# GD32C211 register map
File version: 1.0
CPU: CM23 r0p0, little endian, MPU, FPU, 4 interrupt priority bits
Registers are 32-bit, read-write, reset 0x0 unless marked. A register's access mark holds for its fields unless they carry their own. Offsets are from the block's base; [hi:lo] are bit positions.

## WWDGT — Window watchdog timer
Base 0x40002C00
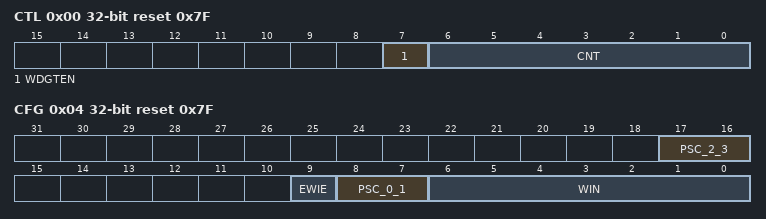
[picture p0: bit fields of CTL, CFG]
0x00 CTL reset 0x7F — Control register
  [7] WDGTEN — Activation bit
  [6:0] CNT — 7-bit counter
0x04 CFG reset 0x7F — Configuration register
  [17:16] PSC_2_3 — Prescaler
  [9] EWIE — Early wakeup interrupt
  [8:7] PSC_0_1 — Prescaler
  [6:0] WIN — 7-bit window value
0x08 STAT — Status register
  [0] EWIF — Early wakeup interrupt flag

## RTC — Real time clock
Base 0x40002800
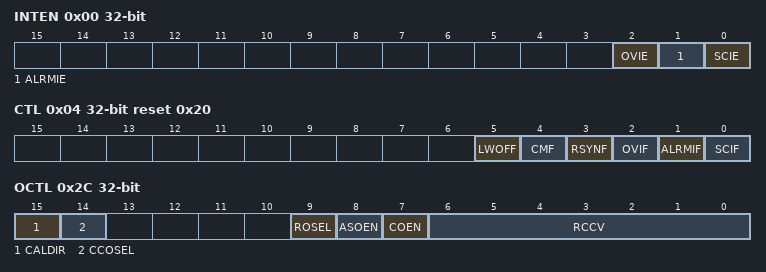
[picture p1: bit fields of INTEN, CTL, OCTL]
0x00 INTEN — RTC interrupt enable register
  [2] OVIE — Overflow interrupt enable
  [1] ALRMIE — Alarm interrupt enable
  [0] SCIE — Second interrupt enable
0x04 CTL access per field reset 0x20 — RTC control register
  [5] LWOFF ro — Last write operation finished flag
  [4] CMF rw — Configuration mode flag
  [3] RSYNF rw — Registers synchronized flag
  [2] OVIF rw — Overflow interrupt flag
  [1] ALRMIF rw — Alarm interrupt flag
  [0] SCIF rw — Second interrupt flag
0x08 PSCH wo — RTC prescaler high register
  [3:0] PSC — RTC prescaler value high
0x0C PSCL wo reset 0x8000 — RTC prescaler low register
  [15:0] PSC — RTC prescaler value low
0x10 DIVH ro — RTC divider high register
  [3:0] DIV — RTC divider value high
0x14 DIVL ro reset 0x8000 — RTC divider low register
  [15:0] DIV — RTC divider value low
0x18 CNTH — RTC counter high register
  [15:0] CNT — RTC counter value high
0x1C CNTL — RTC counter low register
  [15:0] CNT — RTC counter value low
0x20 ALRMH wo reset 0xFFFF — RTC alarm high register
  [15:0] ALRM — RTC alarm value high
0x24 ALRML wo — RTC alarm low register
  [15:0] ALRM — RTC alarm value low
0x2C OCTL — RTC signal output control register
  [15] CALDIR — RTC clock calibration direction
  [14] CCOSEL — RTC clock output selection
  [9] ROSEL — RTC output selection
  [8] ASOEN — RTC alarm or second signal output enable
  [7] COEN — RTC clock calibration output enable
  [6:0] RCCV — RTC clock calibration value

## SPI1 — Serial peripheral interface
Base 0x40003800
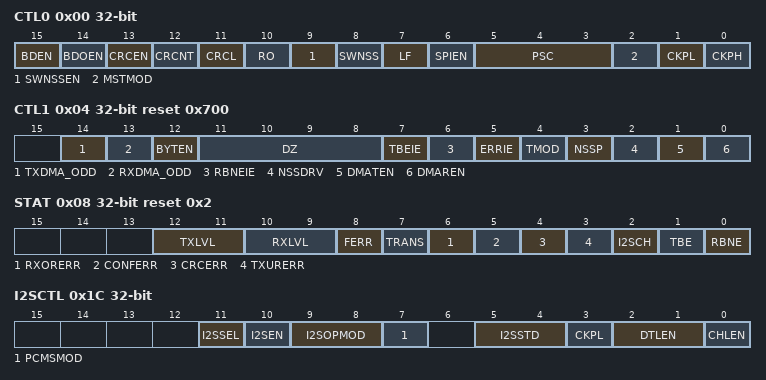
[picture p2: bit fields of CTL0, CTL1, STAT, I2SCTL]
0x00 CTL0 — control register 0
  [15] BDEN — Bidirectional enable
  [14] BDOEN — Bidirectional Transmit output enable
  [13] CRCEN — Hardware CRC calculation enable
  [12] CRCNT — CRC transfer next
  [11] CRCL — CRC length
  [10] RO — Receive only
  [9] SWNSSEN — NSS Software Mode Selection
  [8] SWNSS — NSS Pin Selection In NSS Software Mode
  [7] LF — LSB First Mode
  [6] SPIEN — SPI enable
  [5:3] PSC — Master Clock Prescaler Selection
  [2] MSTMOD — Master Mode Enable
  [1] CKPL — Clock Polarity Selection
  [0] CKPH — Clock Phase Selection
0x04 CTL1 reset 0x700 — control register 1
  [14] TXDMA_ODD — Odd bytes in TX DMA channel
  [13] RXDMA_ODD — Odd bytes in RX DMA channel
  [12] BYTEN — Byte access enable
  [11:8] DZ — Date size
  [7] TBEIE — Transmit Buffer Empty Interrupt Enable
  [6] RBNEIE — Receive Buffer Not Empty Interrupt Enable
  [5] ERRIE — Error interrupt enable
  [4] TMOD — SPI TI Mode Enable
  [3] NSSP — SPI NSS Pulse Mode Enable
  [2] NSSDRV — NSS output enable
  [1] DMATEN — Tx buffer DMA enable
  [0] DMAREN — Rx buffer DMA enable
0x08 STAT access per field reset 0x2 — status register
  [12:11] TXLVL ro — Tx FIFO level
  [10:9] RXLVL ro — Rx FIFO level
  [8] FERR rw — Format Error
  [7] TRANS ro — Transmitting ongoing Bit
  [6] RXORERR ro — Reception Overrun Error Bit
  [5] CONFERR ro — SPI Configuration error
  [4] CRCERR rw — SPI CRC Error Bit
  [3] TXURERR ro — Transmission underrun error bit
  [2] I2SCH ro — I2S channel side
  [1] TBE ro — Transmit Buffer Empty
  [0] RBNE ro — Receive Buffer Not Empty
0x0C DATA
  [15:0] DATA
0x10 CPCPOLY reset 0x7 — CRC polynomial register
  [15:0] CRCPOLY
0x14 RCRC ro — RX CRC register
  [15:0] RCRC — RX RCR register
0x18 TCRC ro — TX CRC register
  [15:0] TCRC — Tx CRC register
0x1C I2SCTL — I2S configuration register
  [11] I2SSEL — I2S mode selection
  [10] I2SEN — I2S Enable
  [9:8] I2SOPMOD — I2S configuration mode
  [7] PCMSMOD — PCM frame synchronization
  [5:4] I2SSTD — I2S standard selection
  [3] CKPL — Idle state clock polarity
  [2:1] DTLEN — Data length to be transferred
  [0] CHLEN — Channel length (number of bits per audio channel)
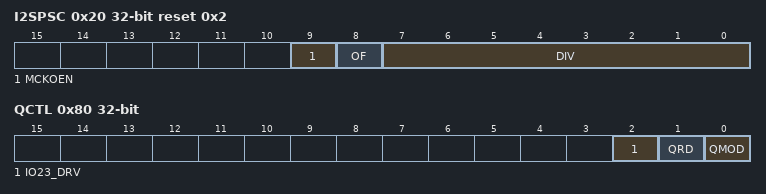
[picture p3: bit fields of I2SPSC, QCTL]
0x20 I2SPSC reset 0x2 — I2S prescaler register
  [9] MCKOEN — I2S_MCK output enable
  [8] OF — Odd factor for the prescaler
  [7:0] DIV — Dividing factor for the prescaler
0x80 QCTL — SPI quad wird control register
  [2] IO23_DRV — Drive IO2 and IO3 enable
  [1] QRD — Quad wire read select
  [0] QMOD — Quad wire mode enable
